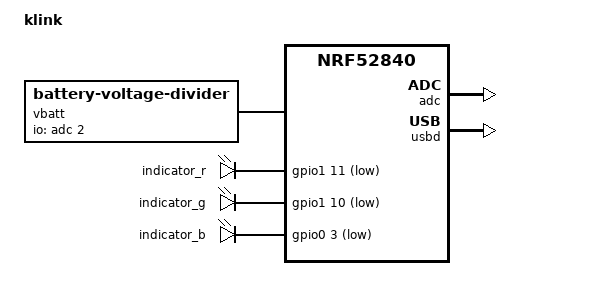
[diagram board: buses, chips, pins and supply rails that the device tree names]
/*
 * klink: nRF52840 controller of the KBDfans Tofu65 3.0 Dual-Mode PCB.
 * Ported to HWMv2 from https://github.com/yangdigi/zmk-keyboards-klink (MIT).
 *
 * SPDX-License-Identifier: MIT
 */

/dts-v1/;
#include <nordic/nrf52840_qiaa.dtsi>
#include <common/nordic/nrf52840_uf2_boot_mode.dtsi>

/ {
    model = "klink";
    compatible = "yang,klink";

    chosen {
        zephyr,code-partition = &code_partition;
        zephyr,sram = &sram0;
        zephyr,flash = &flash0;
        zmk,battery = &vbatt;
    };

    vbatt: vbatt {
        compatible = "zmk,battery-voltage-divider";
        io-channels = <&adc 2>;
        output-ohms = <2000000>;
        full-ohms = <(2000000 + 820000)>;
    };

    // RGB indicator LED (vendor common.overlay): P1.11 R, P1.10 G, P0.03 B, active low.
    indicator_leds: indicator_leds {
        compatible = "gpio-leds";

        indicator_r: indicator_r {
            gpios = <&gpio1 11 GPIO_ACTIVE_LOW>;
        };
        indicator_g: indicator_g {
            gpios = <&gpio1 10 GPIO_ACTIVE_LOW>;
        };
        indicator_b: indicator_b {
            gpios = <&gpio0 3 GPIO_ACTIVE_LOW>;
        };
    };
};

&adc {
    status = "okay";
};

&gpiote {
    status = "okay";
};

&gpio0 {
    status = "okay";
};

&gpio1 {
    status = "okay";
};

zephyr_udc0: &usbd {
    status = "okay";
};

// P0.09/P0.10 are NFC pins; Tofu65 row 4 is on P0.09.
&uicr {
    nfct-pins-as-gpios;
};

// Vendor board enables DCDC (BOARD_ENABLE_DCDC default y).
&reg1 {
    regulator-initial-mode = <NRF5X_REG_MODE_DCDC>;
};

&flash0 {
    partitions {
        compatible = "fixed-partitions";
        #address-cells = <1>;
        #size-cells = <1>;

        sd_partition: partition@0 {
            reg = <0x00000000 0x00026000>;
        };
        code_partition: partition@26000 {
            reg = <0x00026000 0x000c6000>;
        };
        storage_partition: partition@ec000 {
            reg = <0x000ec000 0x00008000>;
        };
        boot_partition: partition@f4000 {
            reg = <0x000f4000 0x0000c000>;
        };
    };
};
